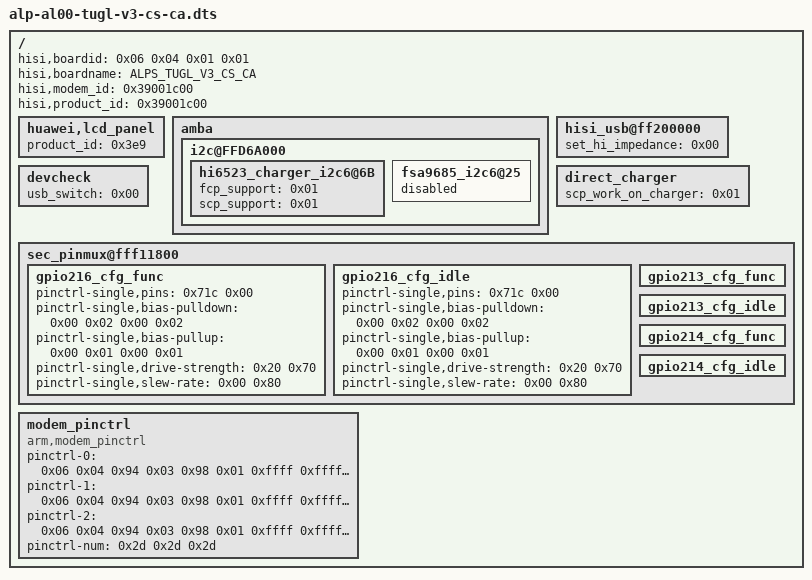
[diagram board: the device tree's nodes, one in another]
/dts-v1/;

/include/ "../variants/alp-al00.dtsi"

/ {
	hisi,boardid = <0x06 0x04 0x01 0x01>;
	hisi,boardname = "ALPS_TUGL_V3_CS_CA";
	hisi,modem_id = <0x39001c00>;
	hisi,product_id = <0x39001c00>;

	huawei,lcd_panel {
		product_id = <0x3e9>;
	};

	amba {
		i2c@FFD6A000 {
			hi6523_charger_i2c6@6B {
				fcp_support = <0x01>;
				scp_support = <0x01>;
			};

			fsa9685_i2c6@25 {
				status = "disabled";
			};
		};
	};

	hisi_usb@ff200000 {
		set_hi_impedance = <0x00>;
	};

	direct_charger {
		scp_work_on_charger = <0x01>;
	};

	devcheck {
		usb_switch = <0x00>;
	};

	sec_pinmux@fff11800 {
		gpio216_cfg_func {
			pinctrl-single,pins = <0x71c 0x00>;
			pinctrl-single,bias-pulldown = <0x00 0x02 0x00 0x02>;
			pinctrl-single,bias-pullup = <0x00 0x01 0x00 0x01>;
			pinctrl-single,drive-strength = <0x20 0x70>;
			pinctrl-single,slew-rate = <0x00 0x80>;
			phandle = <0x654>;
		};

		gpio216_cfg_idle {
			pinctrl-single,pins = <0x71c 0x00>;
			pinctrl-single,bias-pulldown = <0x00 0x02 0x00 0x02>;
			pinctrl-single,bias-pullup = <0x00 0x01 0x00 0x01>;
			pinctrl-single,drive-strength = <0x20 0x70>;
			pinctrl-single,slew-rate = <0x00 0x80>;
			phandle = <0x655>;
		};

		gpio213_cfg_func {
			phandle = <0x656>;
		};

		gpio213_cfg_idle {
			phandle = <0x657>;
		};

		gpio214_cfg_func {
			phandle = <0x658>;
		};

		gpio214_cfg_idle {
			phandle = <0x659>;
		};
	};

	modem_pinctrl {
		compatible = "arm,modem_pinctrl";
		pinctrl-names = "init", "default", "idle";
		pinctrl-0 = <0x06 0x04 0x94 0x03 0x98 0x01 0xffff 0xffff 0x06 0x05 0x98 0x03 0x9c 0x00 0xffff 0xffff 0x07 0x02 0xac 0x02 0xb0 0x00 0xffff 0xffff 0x07 0x03 0xb0 0x01 0xb4 0x00 0xffff 0xffff 0x07 0x04 0xb4 0x01 0xb8 0x00 0xffff 0xffff 0x07 0x05 0xb8 0x01 0xbc 0x00 0xffff 0xffff 0x07 0x06 0xbc 0x01 0xc0 0x00 0xffff 0xffff 0x07 0x07 0xc0 0x01 0xc4 0x00 0xffff 0xffff 0x08 0x00 0xc4 0x01 0xc8 0x00 0x01 0x00 0x08 0x01 0xc8 0x01 0xcc 0x00 0x01 0x00 0x08 0x02 0xcc 0x01 0xd0 0x00 0xffff 0xffff 0x08 0x03 0xd0 0x01 0xd4 0x00 0xffff 0xffff 0x08 0x04 0xd4 0x01 0xd8 0x00 0xffff 0xffff 0x08 0x05 0xd8 0x01 0xdc 0x00 0xffff 0xffff 0x08 0x06 0xdc 0x01 0xe0 0x00 0xffff 0xffff 0x08 0x07 0xe0 0x01 0xe4 0x00 0xffff 0xffff 0x09 0x00 0xe4 0x01 0xe8 0x00 0xffff 0xffff 0x09 0x01 0xe8 0x01 0xec 0x00 0xffff 0xffff 0x09 0x02 0xec 0x01 0xf0 0x00 0xffff 0xffff 0x09 0x03 0xf0 0x01 0xf4 0x00 0xffff 0xffff 0x09 0x04 0xf4 0x01 0xf8 0x00 0xffff 0xffff 0x09 0x05 0xf8 0x01 0xfc 0x00 0xffff 0xffff 0x09 0x06 0xfc 0x01 0x100 0x00 0xffff 0xffff 0x09 0x07 0x100 0x01 0x104 0x00 0xffff 0xffff 0x0a 0x00 0x104 0x01 0x108 0x00 0xffff 0xffff 0x0a 0x01 0x108 0x01 0x10c 0x00 0xffff 0xffff 0x0a 0x02 0x10c 0x01 0x110 0x00 0xffff 0xffff 0x0a 0x03 0x110 0x01 0x114 0x00 0xffff 0xffff 0x0a 0x04 0x114 0x01 0x118 0x00 0xffff 0xffff 0x0a 0x05 0x118 0x01 0x11c 0x00 0xffff 0xffff 0x0a 0x06 0x11c 0x02 0x120 0x00 0xffff 0xffff 0x0a 0x07 0x120 0x02 0x124 0x02 0xffff 0xffff 0x0b 0x00 0x124 0x01 0x128 0x00 0xffff 0xffff 0x0b 0x01 0x128 0x01 0x12c 0x00 0xffff 0xffff 0x0b 0x02 0x12c 0x01 0x130 0x00 0xffff 0xffff 0x0b 0x03 0x130 0x01 0x134 0x00 0xffff 0xffff 0x0b 0x04 0x134 0x01 0x138 0x00 0xffff 0xffff 0x0b 0x05 0x138 0x01 0x13c 0x00 0xffff 0xffff 0x0b 0x06 0x13c 0x01 0x140 0x00 0xffff 0xffff 0x0b 0x07 0x140 0x01 0x144 0x00 0xffff 0xffff 0x0c 0x00 0x144 0x01 0x148 0x00 0xffff 0xffff 0x12 0x05 0xac 0x03 0xdc 0x00 0xffff 0xffff 0x18 0x05 0x4c 0x00 0x78 0x01 0x00 0xffff 0x19 0x06 0x70 0x00 0x9c 0x00 0x00 0xffff 0x1a 0x07 0x718 0x01 0x718 0x02 0x01 0x00>;
		pinctrl-1 = <0x06 0x04 0x94 0x03 0x98 0x01 0xffff 0xffff 0x06 0x05 0x98 0x03 0x9c 0x00 0xffff 0xffff 0x07 0x02 0xac 0x02 0xb0 0x00 0xffff 0xffff 0x07 0x03 0xb0 0x01 0xb4 0x00 0xffff 0xffff 0x07 0x04 0xb4 0x01 0xb8 0x00 0xffff 0xffff 0x07 0x05 0xb8 0x01 0xbc 0x00 0xffff 0xffff 0x07 0x06 0xbc 0x01 0xc0 0x00 0xffff 0xffff 0x07 0x07 0xc0 0x01 0xc4 0x00 0xffff 0xffff 0x08 0x00 0xc4 0xffff 0xc8 0xffff 0xffff 0xffff 0x08 0x01 0xc8 0x01 0xcc 0x00 0x01 0x00 0x08 0x02 0xcc 0x01 0xd0 0x00 0xffff 0xffff 0x08 0x03 0xd0 0x01 0xd4 0x00 0xffff 0xffff 0x08 0x04 0xd4 0x01 0xd8 0x00 0xffff 0xffff 0x08 0x05 0xd8 0x01 0xdc 0x00 0xffff 0xffff 0x08 0x06 0xdc 0x01 0xe0 0x00 0xffff 0xffff 0x08 0x07 0xe0 0x01 0xe4 0x00 0xffff 0xffff 0x09 0x00 0xe4 0x01 0xe8 0x00 0xffff 0xffff 0x09 0x01 0xe8 0x01 0xec 0x00 0xffff 0xffff 0x09 0x02 0xec 0x01 0xf0 0x00 0xffff 0xffff 0x09 0x03 0xf0 0x01 0xf4 0x00 0xffff 0xffff 0x09 0x04 0xf4 0x01 0xf8 0x00 0xffff 0xffff 0x09 0x05 0xf8 0x01 0xfc 0x00 0xffff 0xffff 0x09 0x06 0xfc 0x01 0x100 0x00 0xffff 0xffff 0x09 0x07 0x100 0x01 0x104 0x00 0xffff 0xffff 0x0a 0x00 0x104 0x01 0x108 0x00 0xffff 0xffff 0x0a 0x01 0x108 0x01 0x10c 0x00 0xffff 0xffff 0x0a 0x02 0x10c 0x01 0x110 0x00 0xffff 0xffff 0x0a 0x03 0x110 0x01 0x114 0x00 0xffff 0xffff 0x0a 0x04 0x114 0x01 0x118 0x00 0xffff 0xffff 0x0a 0x05 0x118 0x01 0x11c 0x00 0xffff 0xffff 0x0a 0x06 0x11c 0x02 0x120 0x00 0xffff 0xffff 0x0a 0x07 0x120 0x02 0x124 0x02 0xffff 0xffff 0x0b 0x00 0x124 0x01 0x128 0x00 0xffff 0xffff 0x0b 0x01 0x128 0x01 0x12c 0x00 0xffff 0xffff 0x0b 0x02 0x12c 0x01 0x130 0x00 0xffff 0xffff 0x0b 0x03 0x130 0x01 0x134 0x00 0xffff 0xffff 0x0b 0x04 0x134 0x01 0x138 0x00 0xffff 0xffff 0x0b 0x05 0x138 0x01 0x13c 0x00 0xffff 0xffff 0x0b 0x06 0x13c 0x01 0x140 0x00 0xffff 0xffff 0x0b 0x07 0x140 0x01 0x144 0x00 0xffff 0xffff 0x0c 0x00 0x144 0x01 0x148 0x00 0xffff 0xffff 0x12 0x05 0xac 0x03 0xdc 0x00 0xffff 0xffff 0x18 0x05 0x4c 0xffff 0x78 0xffff 0x00 0xffff 0x19 0x06 0x70 0x00 0x9c 0x00 0x00 0xffff 0x1a 0x07 0x718 0xffff 0x718 0xffff 0xffff 0xffff>;
		pinctrl-2 = <0x06 0x04 0x94 0x03 0x98 0x01 0xffff 0xffff 0x06 0x05 0x98 0x03 0x9c 0x00 0xffff 0xffff 0x07 0x02 0xac 0x02 0xb0 0x00 0xffff 0xffff 0x07 0x03 0xb0 0x01 0xb4 0x00 0xffff 0xffff 0x07 0x04 0xb4 0x01 0xb8 0x00 0xffff 0xffff 0x07 0x05 0xb8 0x01 0xbc 0x00 0xffff 0xffff 0x07 0x06 0xbc 0x01 0xc0 0x00 0xffff 0xffff 0x07 0x07 0xc0 0x01 0xc4 0x00 0xffff 0xffff 0x08 0x00 0xc4 0xffff 0xc8 0xffff 0xffff 0xffff 0x08 0x01 0xc8 0x00 0xcc 0x00 0x00 0x00 0x08 0x02 0xcc 0x01 0xd0 0x00 0xffff 0xffff 0x08 0x03 0xd0 0x01 0xd4 0x00 0xffff 0xffff 0x08 0x04 0xd4 0x01 0xd8 0x00 0xffff 0xffff 0x08 0x05 0xd8 0x01 0xdc 0x00 0xffff 0xffff 0x08 0x06 0xdc 0x01 0xe0 0x00 0xffff 0xffff 0x08 0x07 0xe0 0x01 0xe4 0x00 0xffff 0xffff 0x09 0x00 0xe4 0x01 0xe8 0x00 0xffff 0xffff 0x09 0x01 0xe8 0x01 0xec 0x00 0xffff 0xffff 0x09 0x02 0xec 0x01 0xf0 0x00 0xffff 0xffff 0x09 0x03 0xf0 0x01 0xf4 0x00 0xffff 0xffff 0x09 0x04 0xf4 0x01 0xf8 0x00 0xffff 0xffff 0x09 0x05 0xf8 0x01 0xfc 0x00 0xffff 0xffff 0x09 0x06 0xfc 0x01 0x100 0x00 0xffff 0xffff 0x09 0x07 0x100 0x01 0x104 0x00 0xffff 0xffff 0x0a 0x00 0x104 0x01 0x108 0x00 0xffff 0xffff 0x0a 0x01 0x108 0x01 0x10c 0x00 0xffff 0xffff 0x0a 0x02 0x10c 0x01 0x110 0x00 0xffff 0xffff 0x0a 0x03 0x110 0x01 0x114 0x00 0xffff 0xffff 0x0a 0x04 0x114 0x01 0x118 0x00 0xffff 0xffff 0x0a 0x05 0x118 0x01 0x11c 0x00 0xffff 0xffff 0x0a 0x06 0x11c 0x02 0x120 0x00 0xffff 0xffff 0x0a 0x07 0x120 0x02 0x124 0x02 0xffff 0xffff 0x0b 0x00 0x124 0x01 0x128 0x00 0xffff 0xffff 0x0b 0x01 0x128 0x01 0x12c 0x00 0xffff 0xffff 0x0b 0x02 0x12c 0x01 0x130 0x00 0xffff 0xffff 0x0b 0x03 0x130 0x01 0x134 0x00 0xffff 0xffff 0x0b 0x04 0x134 0x01 0x138 0x00 0xffff 0xffff 0x0b 0x05 0x138 0x01 0x13c 0x02 0xffff 0xffff 0x0b 0x06 0x13c 0x01 0x140 0x00 0xffff 0xffff 0x0b 0x07 0x140 0x01 0x144 0x00 0xffff 0xffff 0x0c 0x00 0x144 0x01 0x148 0x00 0xffff 0xffff 0x12 0x05 0xac 0x03 0xdc 0x00 0xffff 0xffff 0x18 0x05 0x4c 0xffff 0x78 0xffff 0xffff 0xffff 0x19 0x06 0x70 0x00 0x9c 0x00 0x00 0xffff 0x1a 0x07 0x718 0xffff 0x718 0xffff 0xffff 0xffff>;
		pinctrl-num = <0x2d 0x2d 0x2d>;
		status = "ok";
		phandle = <0x65a>;
	};

	__symbols__ {
		gpio216_cfg_func = "/sec_pinmux@fff11800/gpio216_cfg_func";
		gpio216_cfg_idle = "/sec_pinmux@fff11800/gpio216_cfg_idle";
		gpio213_cfg_func = "/sec_pinmux@fff11800/gpio213_cfg_func";
		gpio213_cfg_idle = "/sec_pinmux@fff11800/gpio213_cfg_idle";
		gpio214_cfg_func = "/sec_pinmux@fff11800/gpio214_cfg_func";
		gpio214_cfg_idle = "/sec_pinmux@fff11800/gpio214_cfg_idle";
		modem_pinctrl = "/modem_pinctrl";
	};
};

/include/ "../overlays/alp-al00-tugl-v3-cs-ca.dtsi"
